# STM32H7A3AGI6Q register map
File version: 1.0
Registers are 32-bit, access not given, reset 0x0 unless marked. A register's access mark holds for its fields unless they carry their own. Offsets are from the block's base; [hi:lo] are bit positions; {n}, {i} and the like mark numbered series; 'fields as' and 'values as' point back to an identical list.

## EXTI
Base 0x58000000
0x00 RTSR1
  [21:0] TR
0x04 FTSR1
  [21:0] TR
0x08 SWIER1
  [21:0] SWIER
0x0C SRDPMR1
  [25:0] MR
0x10 SRDPCR1L
  [31:0] PCS
0x14 SRDPCR1H
  [19:6] PCS
0x20 RTSR2
  [19:17] TR
0x24 FTSR2
  [19:17] TR
0x28 SWIER2
  [19:17] SWIER
0x2C SRDPMR2
  [19:2] MR
0x30 SRDPCR2L
  [19:4] PCS
0x34 SRDPCR2H
  [7:0] PCS
0x40 RTSR3
  [21:18] TR
0x44 FTSR3
  [21:18] TR
0x48 SWIER3
  [21:18] SWIER
0x4C SRDPMR3
  [24] MR
0x54 SRDPCR3H
  [17:16] PCS
0x80 CPUIMR1
  [31:0] MR
0x84 CPUEMR1
  [31:0] MR
0x88 CPUPR1
  [21:0] PR
0x90 CPUIMR2
  [31:0] MR
0x94 CPUEMR2
  [31:0] MR
0x98 CPUPR2
  [19:17] PR
0xA0 CPUIMR3
  [24:0] MR
0xA4 CPUEMR3
  [24:0] MR
0xA8 CPUPR3
  [21:18] PR

## SYSCFG
Base 0x58000400
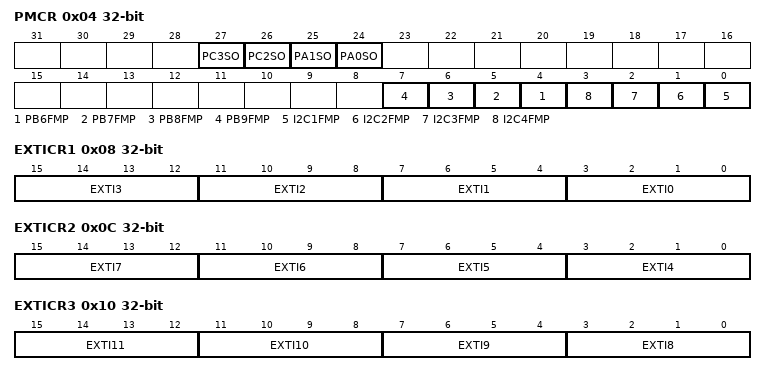
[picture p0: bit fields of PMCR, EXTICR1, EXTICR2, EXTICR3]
0x04 PMCR
  [27] PC3SO, [26] PC2SO, [25] PA1SO, [24] PA0SO, [n-2] PB{n}FMP (n=6..9), [n-1] I2C{n}FMP (n=1..4)
0x08 EXTICR1
  [4n+3:4n] EXTI{n} (n=0..3)
0x0C EXTICR2
  [4n-13:4n-16] EXTI{n} (n=4..7)
0x10 EXTICR3
  [4n-29:4n-32] EXTI{n} (n=8..11)
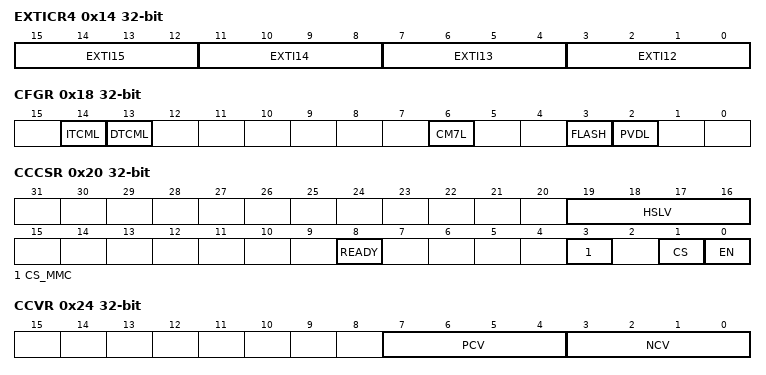
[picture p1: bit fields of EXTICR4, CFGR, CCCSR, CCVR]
0x14 EXTICR4
  [4n-45:4n-48] EXTI{n} (n=12..15)
0x18 CFGR
  [14] ITCML, [13] DTCML, [6] CM7L, [3] FLASH, [2] PVDL
0x20 CCCSR
  [19:16] HSLV, [8] READY, [3] CS_MMC, [1] CS, [0] EN
0x24 CCVR
  [7:4] PCV, [3:0] NCV
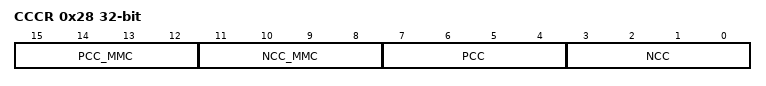
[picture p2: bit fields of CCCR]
0x28 CCCR
  [15:12] PCC_MMC, [11:8] NCC_MMC, [7:4] PCC, [3:0] NCC

## LPUART1
Base 0x58000C00
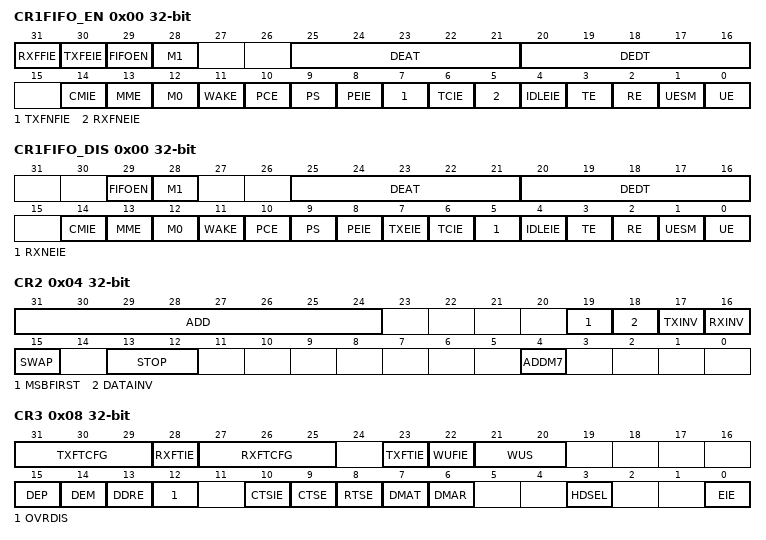
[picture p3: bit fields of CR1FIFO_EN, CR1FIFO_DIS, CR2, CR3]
0x00 CR1FIFO_EN
  [31] RXFFIE, [30] TXFEIE, [29] FIFOEN, [28] M1, [25:21] DEAT, [20:16] DEDT, [14] CMIE, [13] MME, [12] M0, [11] WAKE, [10] PCE, [9] PS, [8] PEIE, [7] TXFNFIE, [6] TCIE, [5] RXFNEIE, [4] IDLEIE, [3] TE, [2] RE, [1] UESM, [0] UE
0x00 CR1FIFO_DIS
  [29] FIFOEN, [28] M1, [25:21] DEAT, [20:16] DEDT, [14] CMIE, [13] MME, [12] M0, [11] WAKE, [10] PCE, [9] PS, [8] PEIE, [7] TXEIE, [6] TCIE, [5] RXNEIE, [4] IDLEIE, [3] TE, [2] RE, [1] UESM, [0] UE
0x04 CR2
  [31:24] ADD, [19] MSBFIRST, [18] DATAINV, [17] TXINV, [16] RXINV, [15] SWAP, [13:12] STOP, [4] ADDM7
0x08 CR3
  [31:29] TXFTCFG, [28] RXFTIE, [27:25] RXFTCFG, [23] TXFTIE, [22] WUFIE, [21:20] WUS, [15] DEP, [14] DEM, [13] DDRE, [12] OVRDIS, [10] CTSIE, [9] CTSE, [8] RTSE, [7] DMAT, [6] DMAR, [3] HDSEL, [0] EIE
0x0C BRR
  [19:0] BRR
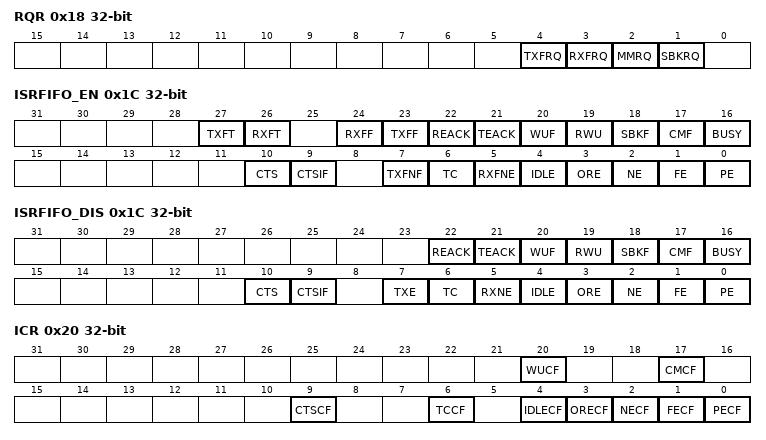
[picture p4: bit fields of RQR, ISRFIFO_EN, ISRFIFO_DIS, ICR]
0x18 RQR
  [4] TXFRQ, [3] RXFRQ, [2] MMRQ, [1] SBKRQ
0x1C ISRFIFO_EN
  [27] TXFT, [26] RXFT, [24] RXFF, [23] TXFF, [22] REACK, [21] TEACK, [20] WUF, [19] RWU, [18] SBKF, [17] CMF, [16] BUSY, [10] CTS, [9] CTSIF, [7] TXFNF, [6] TC, [5] RXFNE, [4] IDLE, [3] ORE, [2] NE, [1] FE, [0] PE
0x1C ISRFIFO_DIS
  [22] REACK, [21] TEACK, [20] WUF, [19] RWU, [18] SBKF, [17] CMF, [16] BUSY, [10] CTS, [9] CTSIF, [7] TXE, [6] TC, [5] RXNE, [4] IDLE, [3] ORE, [2] NE, [1] FE, [0] PE
0x20 ICR
  [20] WUCF, [17] CMCF, [9] CTSCF, [6] TCCF, [4] IDLECF, [3] ORECF, [2] NECF, [1] FECF, [0] PECF
0x24 RDR
  [8:0] RDR
0x28 TDR
  [8:0] TDR
0x2C PRESC
  [3:0] PRESCALER

## COMP1
Base 0x58003800
Same registers: COMP2 0x58003800
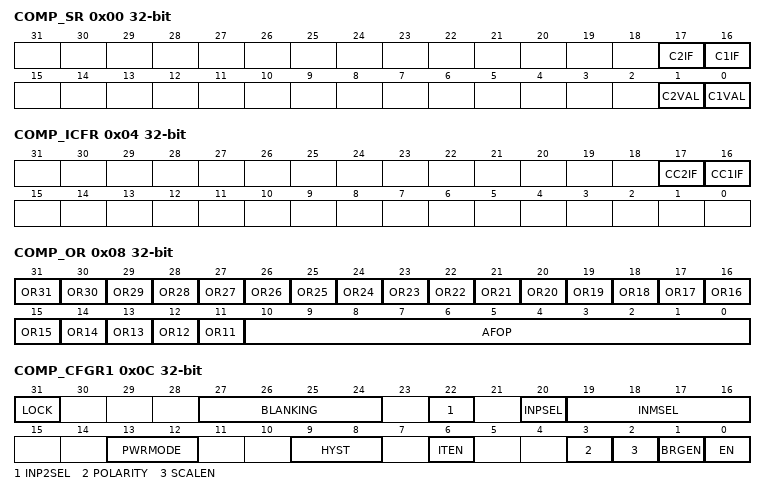
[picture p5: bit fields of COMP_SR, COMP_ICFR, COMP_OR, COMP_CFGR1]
0x00 COMP_SR
  [17] C2IF, [16] C1IF, [1] C2VAL, [0] C1VAL
0x04 COMP_ICFR
  [17] CC2IF, [16] CC1IF
0x08 COMP_OR
  [n] OR{n} (n=11..31), [10:0] AFOP
0x0C COMP_CFGR1
  [31] LOCK, [27:24] BLANKING, [22] INP2SEL, [20] INPSEL, [19:16] INMSEL, [13:12] PWRMODE, [9:8] HYST, [6] ITEN, [3] POLARITY, [2] SCALEN, [1] BRGEN, [0] EN
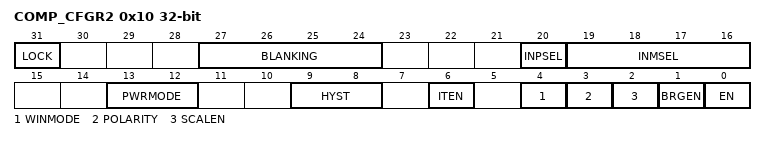
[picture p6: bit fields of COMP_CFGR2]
0x10 COMP_CFGR2
  [31] LOCK, [27:24] BLANKING, [20] INPSEL, [19:16] INMSEL, [13:12] PWRMODE, [9:8] HYST, [6] ITEN, [4] WINMODE, [3] POLARITY, [2] SCALEN, [1] BRGEN, [0] EN

## VREFBUF
Base 0x58003C00
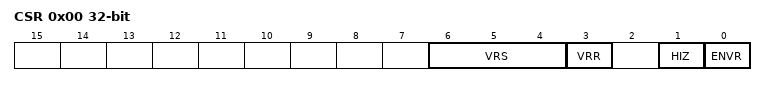
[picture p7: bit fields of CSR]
0x00 CSR
  [6:4] VRS, [3] VRR, [1] HIZ, [0] ENVR
0x04 CCR
  [5:0] TRIM

## RTC
Base 0x58004000
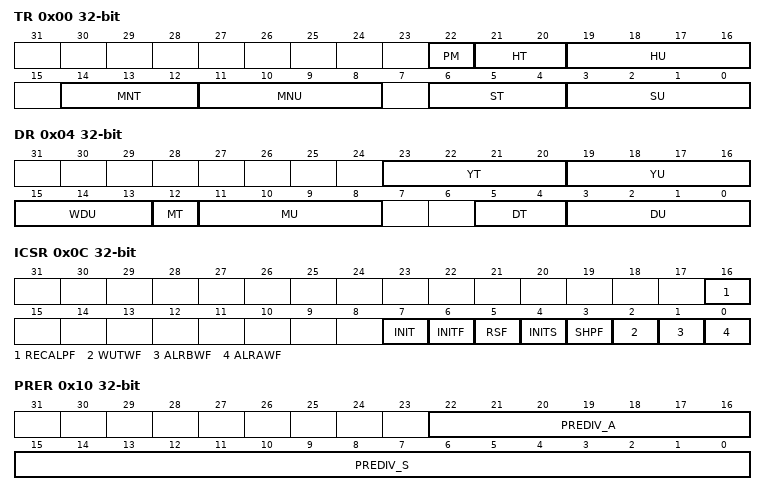
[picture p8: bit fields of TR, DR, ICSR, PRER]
0x00 TR
  [22] PM, [21:20] HT, [19:16] HU, [14:12] MNT, [11:8] MNU, [6:4] ST, [3:0] SU
0x04 DR
  [23:20] YT, [19:16] YU, [15:13] WDU, [12] MT, [11:8] MU, [5:4] DT, [3:0] DU
0x08 SSR
  [15:0] SS
0x0C ICSR
  [16] RECALPF, [7] INIT, [6] INITF, [5] RSF, [4] INITS, [3] SHPF, [2] WUTWF, [1] ALRBWF, [0] ALRAWF
0x10 PRER
  [22:16] PREDIV_A, [15:0] PREDIV_S
0x14 WUTR
  [15:0] WUT
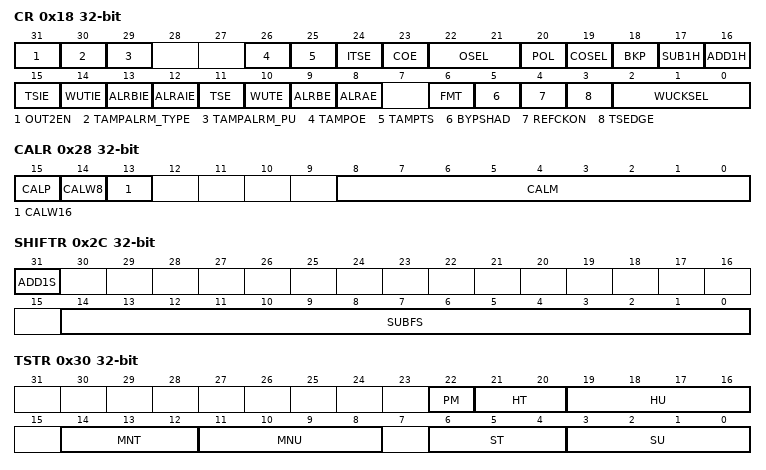
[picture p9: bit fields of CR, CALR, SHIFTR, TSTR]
0x18 CR
  [31] OUT2EN, [30] TAMPALRM_TYPE, [29] TAMPALRM_PU, [26] TAMPOE, [25] TAMPTS, [24] ITSE, [23] COE, [22:21] OSEL, [20] POL, [19] COSEL, [18] BKP, [17] SUB1H, [16] ADD1H, [15] TSIE, [14] WUTIE, [13] ALRBIE, [12] ALRAIE, [11] TSE, [10] WUTE, [9] ALRBE, [8] ALRAE, [6] FMT, [5] BYPSHAD, [4] REFCKON, [3] TSEDGE, [2:0] WUCKSEL
0x24 WPR
  [7:0] KEY
0x28 CALR
  [15] CALP, [14] CALW8, [13] CALW16, [8:0] CALM
0x2C SHIFTR
  [31] ADD1S, [14:0] SUBFS
0x30 TSTR
  fields as TR
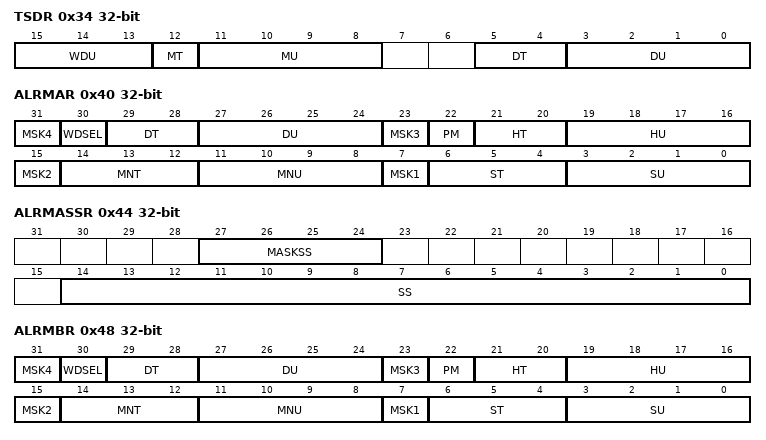
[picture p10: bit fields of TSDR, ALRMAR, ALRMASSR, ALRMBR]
0x34 TSDR
  [15:13] WDU, [12] MT, [11:8] MU, [5:4] DT, [3:0] DU
0x38 TSSSR
  [15:0] SS
0x40 ALRMAR
  [8n-1] MSK{n} (n=1..4), [30] WDSEL, [29:28] DT, [27:24] DU, [22] PM, [21:20] HT, [19:16] HU, [14:12] MNT, [11:8] MNU, [6:4] ST, [3:0] SU
0x44 ALRMASSR
  [27:24] MASKSS, [14:0] SS
0x48 ALRMBR
  fields as ALRMAR
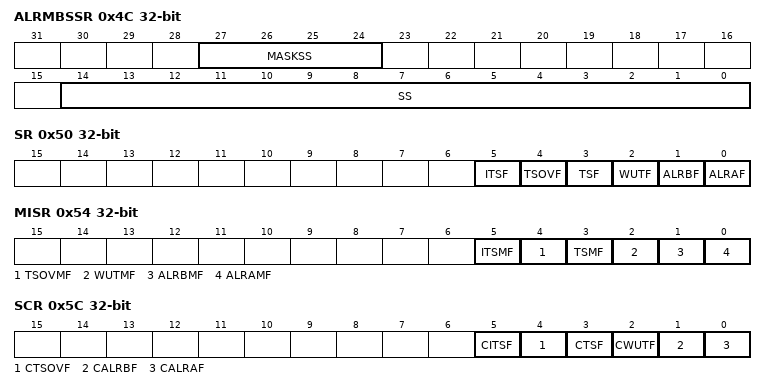
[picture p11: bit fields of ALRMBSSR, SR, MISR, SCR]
0x4C ALRMBSSR
  [27:24] MASKSS, [14:0] SS
0x50 SR
  [5] ITSF, [4] TSOVF, [3] TSF, [2] WUTF, [1] ALRBF, [0] ALRAF
0x54 MISR
  [5] ITSMF, [4] TSOVMF, [3] TSMF, [2] WUTMF, [1] ALRBMF, [0] ALRAMF
0x5C SCR
  [5] CITSF, [4] CTSOVF, [3] CTSF, [2] CWUTF, [1] CALRBF, [0] CALRAF
0x60 CFGR
  [0] OUT2_RM

## TAMP
Base 0x58004400
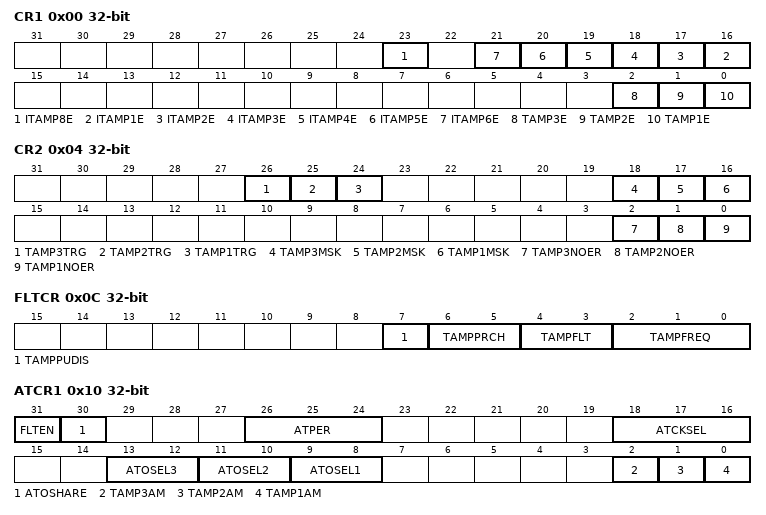
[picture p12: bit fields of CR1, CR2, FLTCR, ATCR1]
0x00 CR1
  [23] ITAMP8E, [n+15] ITAMP{n}E (n=1..6), [2] TAMP3E, [1] TAMP2E, [0] TAMP1E
0x04 CR2
  [26] TAMP3TRG, [25] TAMP2TRG, [24] TAMP1TRG, [18] TAMP3MSK, [17] TAMP2MSK, [16] TAMP1MSK, [2] TAMP3NOER, [1] TAMP2NOER, [0] TAMP1NOER
0x0C FLTCR
  [7] TAMPPUDIS, [6:5] TAMPPRCH, [4:3] TAMPFLT, [2:0] TAMPFREQ
0x10 ATCR1
  [31] FLTEN, [30] ATOSHARE, [26:24] ATPER, [18:16] ATCKSEL, [13:12] ATOSEL3, [11:10] ATOSEL2, [9:8] ATOSEL1, [2] TAMP3AM, [1] TAMP2AM, [0] TAMP1AM
0x14 ATSEEDR
  [31:0] SEED
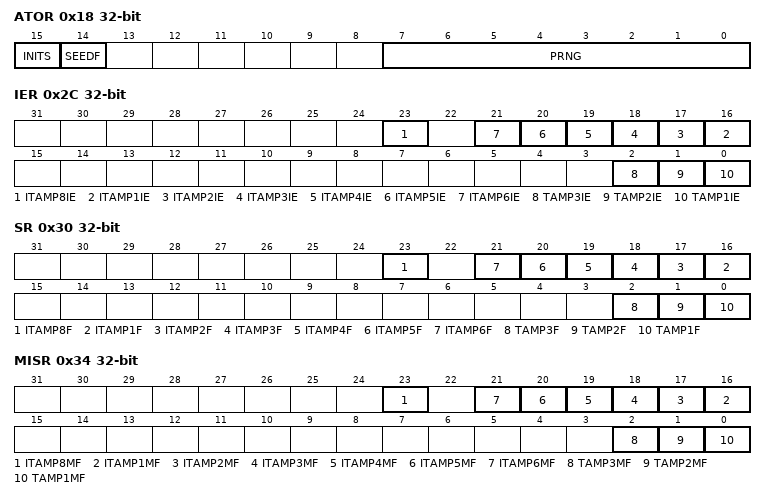
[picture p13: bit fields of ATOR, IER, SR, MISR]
0x18 ATOR
  [15] INITS, [14] SEEDF, [7:0] PRNG
0x2C IER
  [23] ITAMP8IE, [n+15] ITAMP{n}IE (n=1..6), [2] TAMP3IE, [1] TAMP2IE, [0] TAMP1IE
0x30 SR
  [23] ITAMP8F, [n+15] ITAMP{n}F (n=1..6), [2] TAMP3F, [1] TAMP2F, [0] TAMP1F
0x34 MISR
  [23] ITAMP8MF, [n+15] ITAMP{n}MF (n=1..6), [2] TAMP3MF, [1] TAMP2MF, [0] TAMP1MF
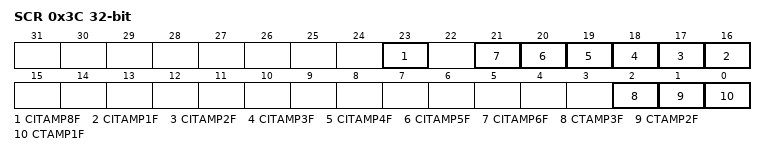
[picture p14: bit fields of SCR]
0x3C SCR
  [23] CITAMP8F, [n+15] CITAMP{n}F (n=1..6), [2] CTAMP3F, [1] CTAMP2F, [0] CTAMP1F
0x40 COUNTR
  [31:0] COUNT
0x50 CFGR
  [0] OUT3_RM
{0x100+4i} BKP{i}R (i=0..31)
  [31:0] BKP

## IWDG
Base 0x58004800
0x00 KR
  [15:0] KEY
0x04 PR
  [2:0] PR
0x08 RLR
  [11:0] RL
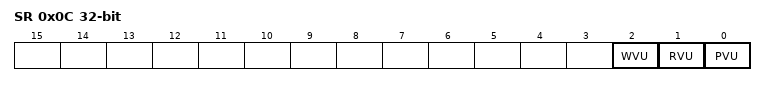
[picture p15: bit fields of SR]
0x0C SR
  [2] WVU, [1] RVU, [0] PVU
0x10 WINR
  [11:0] WIN

## DTS
Base 0x58006800
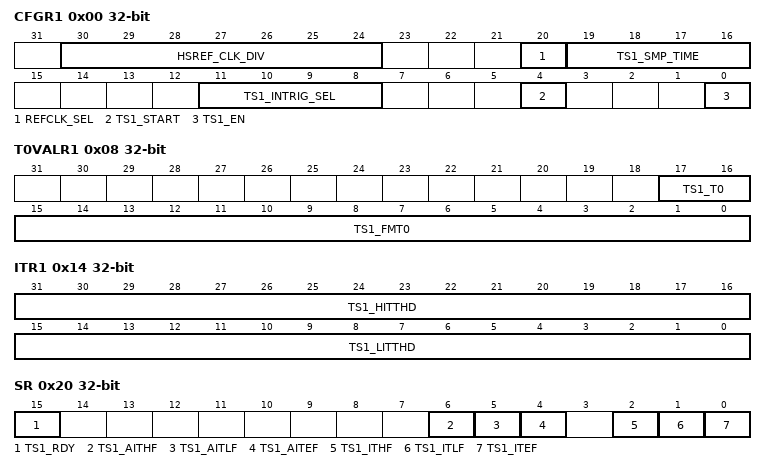
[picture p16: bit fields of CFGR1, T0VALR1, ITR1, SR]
0x00 CFGR1
  [30:24] HSREF_CLK_DIV, [20] REFCLK_SEL, [19:16] TS1_SMP_TIME, [11:8] TS1_INTRIG_SEL, [4] TS1_START, [0] TS1_EN
0x08 T0VALR1
  [17:16] TS1_T0, [15:0] TS1_FMT0
0x10 RAMPVALR
  [15:0] TS1_RAMP_COEFF
0x14 ITR1
  [31:16] TS1_HITTHD, [15:0] TS1_LITTHD
0x1C DR
  [15:0] TS1_MFREQ
0x20 SR
  [15] TS1_RDY, [6] TS1_AITHF, [5] TS1_AITLF, [4] TS1_AITEF, [2] TS1_ITHF, [1] TS1_ITLF, [0] TS1_ITEF
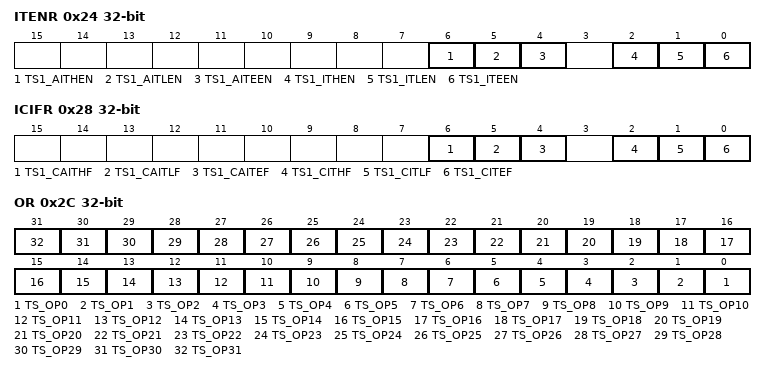
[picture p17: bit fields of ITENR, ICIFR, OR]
0x24 ITENR
  [6] TS1_AITHEN, [5] TS1_AITLEN, [4] TS1_AITEEN, [2] TS1_ITHEN, [1] TS1_ITLEN, [0] TS1_ITEEN
0x28 ICIFR
  [6] TS1_CAITHF, [5] TS1_CAITLF, [4] TS1_CAITEF, [2] TS1_CITHF, [1] TS1_CITLF, [0] TS1_CITEF
0x2C OR
  [n] TS_OP{n} (n=0..31)

## GPIOA
Base 0x58020000
Same registers: GPIOB 0x58020400
0x00 MODER
  [2n+1:2n] MODER{n} (n=0..15)
0x04 OTYPER
  [n] OT{n} (n=0..15)
0x08 OSPEEDR
  [2n+1:2n] OSPEEDR{n} (n=0..15)
0x0C PUPDR
  [2n+1:2n] PUPDR{n} (n=0..15)
0x10 IDR
  [n] IDR{n} (n=0..15)
0x14 ODR
  [n] ODR{n} (n=0..15)
0x18 BSRR
  [n+16] BR{n} (n=0..15), [n] BS{n} (n=0..15)
0x1C LCKR
  [16] LCKK, [n] LCK{n} (n=0..15)
0x20 AFRL
  [4n+3:4n] AFR{n} (n=0..7)
0x24 AFRH
  [4n-29:4n-32] AFR{n} (n=8..15)

## GPIOC
Base 0x58020800
Same registers: GPIOD 0x58020C00, GPIOE 0x58021000, GPIOF 0x58021400, GPIOG 0x58021800, GPIOH 0x58021C00, GPIOI 0x58022000, GPIOJ 0x58022400, GPIOK 0x58022800
Registers as GPIOA; these are added or differ:
0x00 MODER
  [2n+1:2n] MODER{n} (n=2..15), [3:2] MODER, [1:0] MODER0

## PWR
Base 0x58024800
0x00 CR1
  [27] SRDRAMSO, [26] HSITFSO, [25] GFXSO, [24] ITCMSO, [23] AHBRAM2SO, [22] AHBRAM1SO, [21] AXIRAM3SO, [20] AXIRAM2SO, [19] AXIRAM1SO, [18:17] ALS, [16] AVDEN, [15:14] SVOS, [13] AVD_READY, [12] BOOSTE, [9] FLPS, [8] DBP, [7:5] PLS, [4] PVDE, [0] LPDS
0x04 CSR1
  [17] MMCVDO, [16] AVDO, [15:14] ACTVOS, [13] ACTVOSRDY, [4] PVDO
0x08 CR2
  [23] TEMPH, [22] TEMPL, [16] BRRDY, [4] MONEN, [0] BREN
0x0C CR3
  [26] USB33RDY, [25] USBREGEN, [24] USB33DEN, [16] SMPSEXTRDY, [9] VBRS, [8] VBE, [5:4] SMPSLEVEL, [3] SMPSEXTHP, [2] SMPSEN, [1] LDOEN, [0] BYPASS
0x10 CPUCR
  [11] RUN_SRD, [9] CSSF, [6] SBF, [5] STOPF, [2] PDDS_SRD, [0] RETDS_CD
0x18 SRDCR
  [15:14] VOS, [13] VOSRDY
0x20 WKUPCR
  [n-1] WKUPC{n} (n=1..6)
0x24 WKUPFR
  [n-1] WKUPF{n} (n=1..6)
0x28 WKUPEPR
  [2n+15:2n+14] WKUPPUPD{n} (n=1..6), [n+7] WKUPP{n} (n=1..6), [n-1] WKUPEN{n} (n=1..6)
